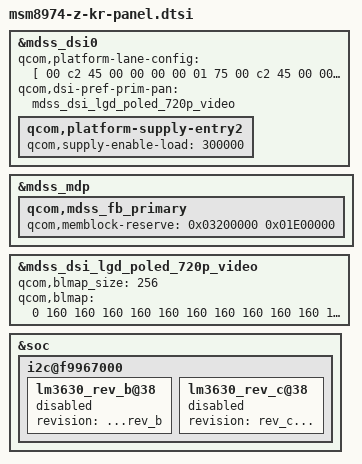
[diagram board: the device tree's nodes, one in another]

/* Copyright (c) 2012, Code Aurora Forum. All rights reserved.
 *
 * This program is free software; you can redistribute it and/or modify
 * it under the terms of the GNU General Public License version 2 and
 * only version 2 as published by the Free Software Foundation.
 *
 * This program is distributed in the hope that it will be useful,
 * but WITHOUT ANY WARRANTY; without even the implied warranty of
 * MERCHANTABILITY or FITNESS FOR A PARTICULAR PURPOSE.  See the
 * GNU General Public License for more details.
 */

&mdss_dsi0 {
	qcom,platform-lane-config = [
		00 c2 45 00 00 00 00 01 75 // lane0 config
		00 c2 45 00 00 00 00 01 75 // lane1 config
		00 c2 45 00 00 00 00 01 75 // lane2 config
		00 c2 45 00 00 00 00 01 75 // lane3 config
		00 02 45 00 00 00 00 01 97 // Clk ln config
	];
	qcom,dsi-pref-prim-pan = <&mdss_dsi_lgd_poled_720p_video>;
	qcom,platform-supply-entry2 {
		qcom,supply-enable-load = <300000>;
	};

};

&mdss_mdp {
	qcom,mdss_fb_primary {
		qcom,memblock-reserve = <0x03200000 0x01E00000>;
	};
};

&mdss_dsi_lgd_poled_720p_video {
	qcom,blmap_size = <256>;
	qcom,blmap = <
		0
		// unused area(001-054)
		160 160 160 160 160 160 160 160 160 160 160 160 160 160 160
		160 160 160 160 160 160 160 160 160 160 160 160 160 160 160
		160 160 160 160 160 160 160 160 160 160 160 160 160 160 160
		160 160 160 160 160 160 160 160 160
		// used area(055-255)
		178 178 178 178 178 178 178 178 178 178 178 178 178 178 178		// 055-069
		178 179 179 179 179 179 179 179 179 179 179 180 180 180 180		// 070-084
		180 180 180 180 181 181 181 181 181 182 182 182 182 182 183		// 085-099
		183 183 183 183 184 184 184 184 185 185 185 186 186 186 186		// 100-114
		187 187 187 188 188 189 189 189 190 190 191 191 191 192 192		// 115-129
		193 193 193 194 194 195 195 195 196 196 197 197 197 198 198		// 130-144
		199 199 199 200 200 201 201 201 202 202 203 203 203 204 204		// 145-159
		205 205 205 206 206 207 207 208 208 209 209 210 210 211 211		// 160-174
		212 212 213 213 214 214 215 215 216 216 217 217 218 218 219		// 175-189
		219 220 221 221 222 223 223 224 224 225 225 226 227 227 228		// 190-204
		229 229 230 230 231 231 232 232 233 233 234 234 235 235 236		// 205-219
		236 237 237 238 238 239 239 240 240 241 241 242 243 243 244		// 220-234
		245 245 246 246 247 247 248 248 249 249 250 250 251 251 252		// 235-249
		252 253 253 254 254 255											// 250-255
	>;
};

&soc {
	i2c@f9967000 {
		lm3630_rev_b@38 {
			status = "disable";
			revision = "...rev_b";
		};

		lm3630_rev_c@38 {
			status = "disable";
			revision = "rev_c...";
		};
	};
};
